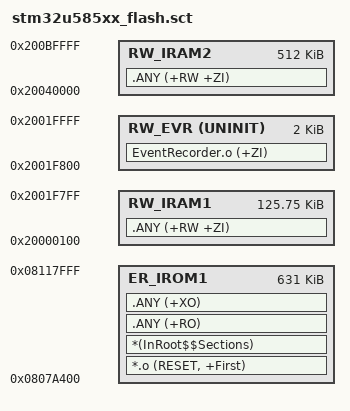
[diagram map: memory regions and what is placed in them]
; *************************************************************
; *** Scatter-Loading Description File generated by uVision ***
; *************************************************************

LR_IROM1 0x0807A400 0x0009DC00  {    ; load region size_region
  ER_IROM1 0x0807A400 0x0009DC00  {  ; load address = execution address
   *.o (RESET, +First)
   *(InRoot$$Sections)
   .ANY (+RO)
   .ANY (+XO)
  }
  RW_IRAM1 0x20000100 0x0001F700  {  ; RW data
   .ANY (+RW +ZI)
  }
  RW_IRAM2 0x20040000 0x00080000  {  ; RW data
   .ANY (+RW +ZI)
  }
  RW_EVR 0x2001F800 UNINIT 0x00000800  {
    EventRecorder.o (+ZI)
  }
}

